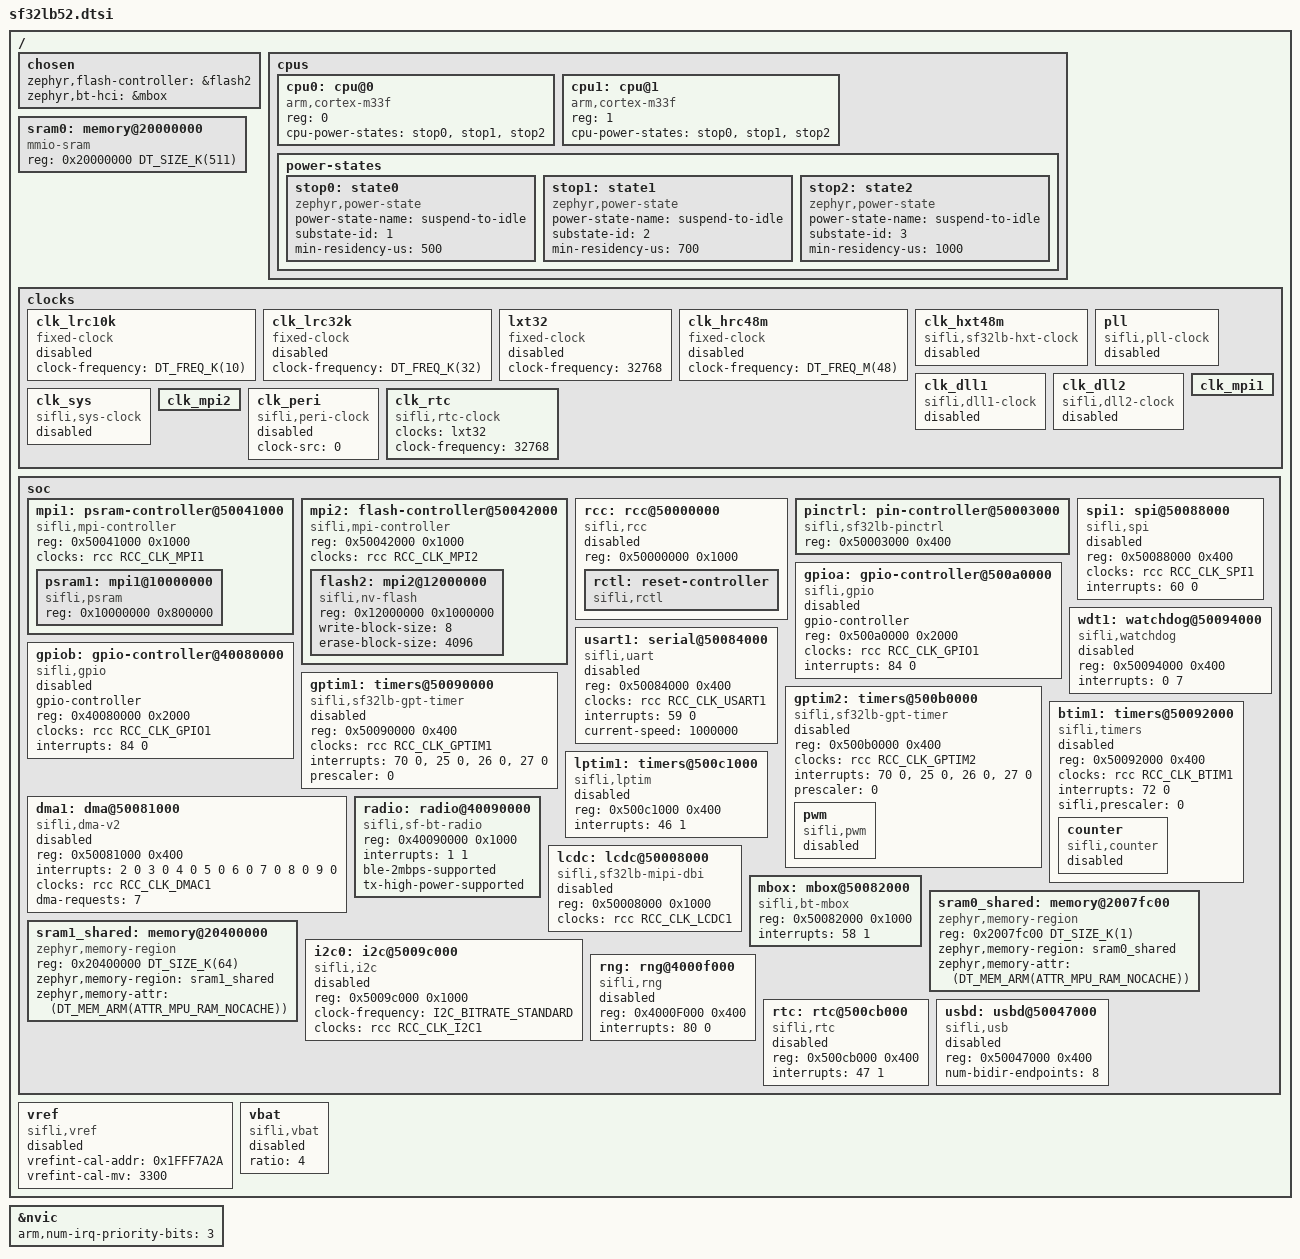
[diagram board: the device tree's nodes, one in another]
/*
 * SPDX-FileCopyrightText: 2025 SiFli Technologies(Nanjing) Co., Ltd
 *
 * SPDX-License-Identifier: Apache-2.0
 */

#include <arm/armv8-m.dtsi>
#include <zephyr/dt-bindings/i2c/i2c.h>
#include <zephyr/dt-bindings/gpio/gpio.h>
#include <zephyr/dt-bindings/pwm/pwm.h>
#include <zephyr/dt-bindings/adc/adc.h>
#include <zephyr/dt-bindings/memory-attr/memory-attr-arm.h>
#include <zephyr/dt-bindings/clock/sf32lb525-clock.h>
#include <freq.h>
#include <mem.h>

#define SF32LB_RESET(a,b)
#define SF32LB_SRC_MSI
#define CLK48_SEL(a)

/ {
	chosen {
		//zephyr,entropy = &rng1;
		zephyr,flash-controller = &flash2;
		zephyr,bt-hci = &mbox;
	};

	cpus {
		#address-cells = <1>;
		#size-cells = <0>;

		cpu0: cpu@0 {
			device_type = "cpu";
			compatible = "arm,cortex-m33f";
			reg = <0>;
			cpu-power-states = <&stop0 &stop1 &stop2>;
		};

		cpu1: cpu@1 {
			device_type = "cpu";
			compatible = "arm,cortex-m33f";
			reg = <1>;
			cpu-power-states = <&stop0 &stop1 &stop2>;
		};

		power-states {
			stop0: state0 {
				compatible = "zephyr,power-state";
				power-state-name = "suspend-to-idle";
				substate-id = <1>;
				min-residency-us = <500>;
			};
			stop1: state1 {
				compatible = "zephyr,power-state";
				power-state-name = "suspend-to-idle";
				substate-id = <2>;
				min-residency-us = <700>;
			};
			stop2: state2 {
				compatible = "zephyr,power-state";
				power-state-name = "suspend-to-idle";
				substate-id = <3>;
				min-residency-us = <1000>;
			};
		};
	};

	sram0: memory@20000000 {
		compatible = "mmio-sram";
        reg = <0x20000000 DT_SIZE_K(511)>;
	};

	clocks {
		clk_lrc10k: clk_lrc10k {
			#clock-cells = <0>;
			compatible = "fixed-clock";
			clock-frequency = <DT_FREQ_K(10)>;
			status = "disabled";
		};

		clk_lrc32k: clk_lrc32k {
			#clock-cells = <0>;
			compatible = "fixed-clock";
			clock-frequency = <DT_FREQ_K(32)>;
			status = "disabled";
		};

		lxt32: lxt32 {
			#clock-cells = <0>;
			compatible = "fixed-clock";
			clock-frequency = <32768>;
			status = "disabled";
		};

		clk_hrc48m: clk_hrc48m {
			#clock-cells = <0>;
			compatible = "fixed-clock";
			clock-frequency = <DT_FREQ_M(48)>;
			status = "disabled";
		};

		clk_hxt48m: clk_hxt48m {
			#clock-cells = <0>;
			compatible = "sifli,sf32lb-hxt-clock";
			status = "disabled";
		};

		pll: pll {
			#clock-cells = <0>;
			compatible = "sifli,pll-clock";
			status = "disabled";
		};

		clk_dll1: clk_dll1 {
			#clock-cells = <0>;
			compatible = "sifli,dll1-clock";
			status = "disabled";
		};

		clk_dll2: clk_dll2 {
			#clock-cells = <0>;
			compatible = "sifli,dll2-clock";
			status = "disabled";
		};

		clk_sys: clk_sys {
			#clock-cells = <0>;
			compatible = "sifli,sys-clock";
			//clock-src = <0>;//FXIME: using CLK_HRC48 CLK_HXT48 CLK_DLL1
			//hdiv = <0>;
			//pdiv1 = <0>;
			//pdiv2 = <0>;
			status = "disabled";
		};

		clk_mpi1: clk_mpi1 {

		};

		clk_mpi2: clk_mpi2 {

		};

		clk_peri: clk_peri {
			#clock-cells = <2>;
			compatible = "sifli,peri-clock";
			clock-src = <0>;//TODO:
			status = "disabled";
		};

		clk_rtc: clk_rtc {
			compatible = "sifli,rtc-clock";
			clocks = <&lxt32>;
			clock-frequency = <32768>;
			#clock-cells = <0>;
		};
	};

	soc {
		mpi1: psram-controller@50041000 {
			compatible = "sifli,mpi-controller", "sifli,sf32lb52-flash-controller";
			reg = <0x50041000 0x1000>;
			clocks = <&rcc RCC_CLK_MPI1>;

			#address-cells = <1>;
			#size-cells = <1>;

			psram1: mpi1@10000000 {
				compatible = "sifli,psram", "soc-psram";
				reg = <0x10000000 0x800000>;
			};
		};

		mpi2: flash-controller@50042000 {
			compatible = "sifli,mpi-controller", "sifli,sf32lb-flash-controller";
			reg = <0x50042000 0x1000>;
			clocks = <&rcc RCC_CLK_MPI2>;

			#address-cells = <1>;
			#size-cells = <1>;

			flash2: mpi2@12000000 {
				compatible = "sifli,nv-flash", "soc-nv-flash";
				reg = <0x12000000 0x1000000>;
				write-block-size = <8>;
				erase-block-size = <4096>;
			};
		};

		rcc: rcc@50000000 {
			compatible = "sifli,rcc";
			#clock-cells = <1>;
			reg = <0x50000000 0x1000>;
			status = "disabled";

			rctl: reset-controller {
				compatible = "sifli,rctl";
				#reset-cells = <1>;
			};
		};

		pinctrl: pin-controller@50003000 {
			compatible = "sifli,sf32lb-pinctrl";
			reg = <0x50003000 0x400>;
			status = "okay";
		};

		gpioa: gpio-controller@500a0000 {
			compatible = "sifli,gpio";
			gpio-controller;
			#gpio-cells = <2>;
			reg = <0x500a0000 0x2000>;
			clocks = <&rcc RCC_CLK_GPIO1>;
			interrupts = <84 0>;
			status = "disabled";
		};

		gpiob: gpio-controller@40080000 {
			compatible = "sifli,gpio";
			gpio-controller;
			#gpio-cells = <2>;
			reg = <0x40080000 0x2000>;
			clocks = <&rcc RCC_CLK_GPIO1>;
			interrupts = <84 0>;
			status = "disabled";
		};
/*
		adc1: adc@500a4000 {
			compatible = "sifli,adc";
			reg = <0x500a4000 0x1000>;
			clocks = <&rcc RCC_CLK_ADC1>;
			interrupts = <85 0>;
			status = "disabled";

			#io-channels-cells = <2>;
			#address-cells = <1>;
			#size-cells = <0>;

			io-channel@17 {
				reg = <17>;
				sifli,adc-channel-name = "vref";
				sifli,adc-channel-type = "vrefint";
				sifli,adc-channel-sampling-time = <ADC_SAMPLING_TIME_640_CYCLES>;
			};

			io-channel@18 {
				reg = <18>;
				sifli,adc-channel-name = "vbat";
				sifli,adc-channel-type = "vbat";
				sifli,adc-channel-sampling-time = <ADC_SAMPLING_TIME_640_CYCLES>;
			};
		};
*/
		spi1: spi@50088000 {
			compatible = "sifli,spi";
			#address-cells = <1>;
			#size-cells = <0>;
			reg = <0x50088000 0x400>;
			clocks = <&rcc RCC_CLK_SPI1>;
			interrupts = <60 0>;
			status = "disabled";
		};

		wdt1: watchdog@50094000 {
			compatible = "sifli,watchdog";
			reg = <0x50094000 0x400>;
			status = "disabled";
			//clocks = <&rcc RCC_CLK_WDT1>;
			interrupts = <0 7>;
		};

		usart1: serial@50084000 {
			compatible = "sifli,uart";
			reg = <0x50084000 0x400>;
			clocks = <&rcc RCC_CLK_USART1>;
			//resets = <&rctl SF32LB_RESET(APB2, 14U)>;
			interrupts = <59 0>;
			current-speed = <1000000>;
			status = "disabled";
		};

		gptim1: timers@50090000 {
			compatible = "sifli,sf32lb-gpt-timer";
			reg = <0x50090000 0x400>;
			clocks = <&rcc RCC_CLK_GPTIM1>;
			//resets = <&rctl SF32LB_RESET(APB2, 11U)>;
			interrupts = <70 0>, <25 0>, <26 0>, <27 0>;
			interrupt-names = "brk", "up", "trgcom", "cc";
			prescaler = <0>;
			status = "disabled";
/*
			pwm {
				compatible = "sifli,pwm";
				status = "disabled";
				#pwm-cells = <3>;
			};
			counter {
				compatible = "sifli,counter";
				status = "disabled";
			};
*/
		};

		gptim2: timers@500b0000 {
			compatible = "sifli,sf32lb-gpt-timer";
			reg = <0x500b0000 0x400>;
			clocks = <&rcc RCC_CLK_GPTIM2>;
			interrupts = <70 0>, <25 0>, <26 0>, <27 0>;
			interrupt-names = "brk", "up", "trgcom", "cc";
			prescaler = <0>;
			status = "disabled";

			pwm {
				compatible = "sifli,pwm";
				status = "disabled";
				#pwm-cells = <3>;
			};
		};

		btim1: timers@50092000 {
			compatible = "sifli,timers";
			reg = <0x50092000 0x400>;
			clocks = <&rcc RCC_CLK_BTIM1>;
			//resets = <&rctl SF32LB_RESET(APB1L, 0U)>;
			interrupts = <72 0>;
			interrupt-names = "global";
			sifli,prescaler = <0>;
			status = "disabled";

			counter {
				compatible = "sifli,counter";
				status = "disabled";
			};
		};

		dma1: dma@50081000 {
			compatible = "sifli,dma-v2";
			#dma-cells = <3>;
			reg = <0x50081000 0x400>;
			interrupts = <2 0 3 0 4 0 5 0 6 0 7 0 8 0 9 0>;
			clocks = <&rcc RCC_CLK_DMAC1>;
			dma-requests = <7>;
			status = "disabled";
		};

		lptim1: timers@500c1000 {
			compatible = "sifli,lptim";
			//clocks = <&rcc SF32LB_CLOCK(APB1, 31U)>;
			#address-cells = <1>;
			#size-cells = <0>;
			reg = <0x500c1000 0x400>;
			interrupts = <46 1>;
			interrupt-names = "wakeup";
			status = "disabled";
		};

		radio: radio@40090000 {
			compatible = "sifli,sf-bt-radio";
			reg = <0x40090000 0x1000>;
			interrupts = <1 1>;
			status = "okay";
			ble-2mbps-supported;
			tx-high-power-supported;
		};

		lcdc: lcdc@50008000 {
			compatible = "sifli,sf32lb-mipi-dbi";
			reg = <0x50008000 0x1000>;
			#address-cells = <1>;
			#size-cells = <0>;
			clocks = <&rcc RCC_CLK_LCDC1>;
			status = "disabled";
		};

		mbox: mbox@50082000 {
			compatible = "sifli,bt-mbox";
			reg = <0x50082000 0x1000>;
			interrupts = <58 1>;
			status = "okay";
		};

		sram0_shared: memory@2007fc00 {
			/* Last 1 kB of sram0 */
			compatible = "zephyr,memory-region", "mmio-sram";
			reg = <0x2007fc00 DT_SIZE_K(1)>;
			device_type = "memory";
			zephyr,memory-region = "sram0_shared";
			zephyr,memory-attr = <(DT_MEM_ARM(ATTR_MPU_RAM_NOCACHE))>;
		};

		sram1_shared: memory@20400000 {
			/* Last 1 kB of sram0 */
			compatible = "zephyr,memory-region", "mmio-sram";
			reg = <0x20400000 DT_SIZE_K(64)>;
			device_type = "memory";
			zephyr,memory-region = "sram1_shared";
			zephyr,memory-attr = <(DT_MEM_ARM(ATTR_MPU_RAM_NOCACHE))>;
		};

		i2c0: i2c@5009c000 {
			compatible = "sifli,i2c";
			reg = <0x5009c000 0x1000>;
			#address-cells = <1>;
			#size-cells = <0>;
			clock-frequency = <I2C_BITRATE_STANDARD>;
			clocks = <&rcc RCC_CLK_I2C1>;
			status = "disabled";
		};

		rng: rng@4000f000 {
			compatible = "sifli,rng";
			reg = <0x4000F000 0x400>;
			interrupts = <80 0>;
			//clocks = <&rcc SF32LB_CLOCK(AHB2, 18U)>,
			status = "disabled";
		};

		rtc: rtc@500cb000 {
			compatible = "sifli,rtc";
			reg = <0x500cb000 0x400>;
			interrupts = <47 1>;
			status = "disabled";
		};

		usbd: usbd@50047000 {
			compatible = "sifli,usb";
			reg = <0x50047000 0x400>;
			num-bidir-endpoints = <8>;
			status = "disabled";
		};

	};
  	vref: vref {
		compatible = "sifli,vref";
		vrefint-cal-addr = <0x1FFF7A2A>;
		vrefint-cal-mv = <3300>;
		//io-channels = <&adc1 17>;
		status = "disabled";
	};

	vbat: vbat {
		compatible = "sifli,vbat";
		ratio = <4>;
		//io-channels = <&adc1 18>;
		status = "disabled";
	};

};

&nvic {
	arm,num-irq-priority-bits = <3>;
};
